# STM32WBA52 register map
File version: 0.1
CPU: CM33 r0p1, little endian, MPU, FPU, 4 interrupt priority bits
Registers are 32-bit, read-write, reset 0x0 unless marked. A register's access mark holds for its fields unless they carry their own. Offsets are from the block's base; [hi:lo] are bit positions; {n}, {i} and the like mark numbered series; <NAME> marks a mode.

## PWR — Power control
Base 0x46020800
Same registers: SEC_PWR 0x56020800
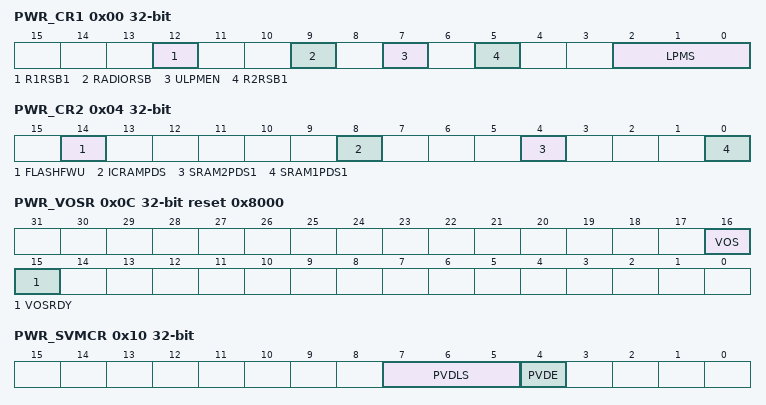
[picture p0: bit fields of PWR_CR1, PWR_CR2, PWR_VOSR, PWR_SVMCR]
0x00 PWR_CR1 — PWR control register 1
  [12] R1RSB1 — SRAM1 retention in Standby mode This bit is used to keep the SRAM1 content in Standby retention mode.
    0=SRAM1 content not retained in Standby mode; 1=SRAM1 content retained in Standby mode
  [9] RADIORSB — 2.4 GHz RADIO SRAMs (RXTXRAM and Sequence RAM) and Sleep clock retention in Standby mode. This bit is used to keep the 2.4 GHz RADIO SRAMs content in Standby retention mode and the 2.4 GHz RADIO sleep timer counter operational.
    0=2.4 GHz RADIO SRAMs and sleep timer content not retained in Standby mode; 1=2.4 GHz RADIO SRAMs and sleep timer content retained in Standby mode
  [7] ULPMEN — BOR0 ultra-low-power mode. This bit is used to reduce the consumption by configuring the BOR0 in discontinuous mode for Stop 1 and Standby modes. Discontinuous mode is only available when BOR levels 1 to 4 and PVD are disabled. Note: This bit must be set to reach the lowest power consumption in the low-power modes. Note: This bit must not be set together with autonomous peripherals using HSI16 as kernel clock. Note: When BOR level 1 to 4 or PVD is enabled continuous mode applies independent from ULPMEN.
    0=BOR0 operating in continuous (normal) mode in all operating modes; 1=BOR0 operating in discontinuous (ultra-low-power) mode in Stop 1 and Standby modes
  [5] R2RSB1 — SRAM2 retention in Standby mode This bit is used to keep the SRAM2 content in Standby retention mode.
    0=SRAM2 content not retained in Standby mode; 1=SRAM2 content retained in Standby mode
  [2:0] LPMS — Low-power mode selection These bits select the low-power mode entered when the CPU enters the SleepDeep mode. 10x: Standby mode others reserved
    0=Stop 0 mode; 1=Stop 1 mode
0x04 PWR_CR2 — PWR control register 2
  [14] FLASHFWU — Flash memory fast wakeup from Stop modes (Stop 0, 1) This bit is used to obtain the best trade-off between low-power consumption and wakeup time when exiting the Stop 0 or Stop 1 modes. When this bit is set, the Flash memory remains in normal mode in Stop 0 and Stop 1 modes, which offers a faster startup time with higher consumption.
    0=Flash memory enters low-power mode in Stop 0 and Stop 1 modes (lower-power consumption); 1=Flash memory remains in normal mode in Stop 0 and Stop 1 modes (faster wakeup time)
  [8] ICRAMPDS — ICACHE SRAM power-down in Stop modes (Stop 0, 1)
    0=ICACHE SRAM content retained in Stop modes; 1=ICACHE SRAM content lost in Stop modes
  [4] SRAM2PDS1 — SRAM2 power-down in Stop modes (Stop 0, 1) Note: The SRAM2 retention in Standby mode is controlled by R2RSB1 bit in PWR_CR1.
    0=SRAM2 content retained in Stop modes; 1=SRAM2 content lost in Stop modes
  [0] SRAM1PDS1 — SRAM1 power-down in Stop modes (Stop 0, 1) Note: The SRAM1 retention in Standby mode is controlled by R1RSB1 bit in PWR_CR1.
    0=SRAM1 content retained in Stop modes; 1=SRAM1 content lost in Stop modes
0x08 PWR_CR3 — PWR control register 3
  [2] FSTEN — Fast soft start
    0=LDO fast startup disabled (limited inrush current); 1=LDO fast startup enabled
0x0C PWR_VOSR access per field reset 0x8000 — PWR voltage scaling register
  [16] VOS rw — Voltage scaling range selection Set a and cleared by software. Cleared by hardware when entering Stop 1 mode. Access can be secured by RCC SYSCLKSEC. When secure, a non-secure read/write access is RAZ/WI. It does not generate an illegal access interrupt. This bit can be protected against unprivileged access when secure with PWR SPRIV or when non-secure with PWR NSPRIV.
    0=Range 2 (lowest power); 1=Range 1 (highest frequency)
  [15] VOSRDY ro — Ready bit for V<sub>CORE</sub> voltage scaling output selection Set and cleared by hardware. When decreasing the voltage scaling range, VOSRDY must be one before increasing the SYSCLK frequency.
    0=Not ready, voltage level < VOS selected level; 1=Ready, voltage level ≥ VOS selected level
0x10 PWR_SVMCR — PWR supply voltage monitoring control register
  [7:5] PVDLS — Programmable voltage detector level selection These bits select the voltage threshold detected by the programmable voltage detector:
    0=V<sub>PVD0</sub> ~ 2.0 V; 1=V<sub>PVD1</sub> ~ 2.2 V; 2=V<sub>PVD2</sub> ~ 2.4 V; 3=V<sub>PVD3</sub> ~ 2.5 V; 4=V<sub>PVD4</sub> ~ 2.6 V; 5=V<sub>PVD5</sub> ~ 2.8 V; 6=V<sub>PVD6</sub> ~ 2.9 V; 7=External input analog voltage PVD_IN (compared internally to VREFINT), The I/O used as PVD_IN input, must be configured in analog mode in the GPIO register
  [4] PVDE — Programmable voltage detector enable
    0=Programmable voltage detector disabled; 1=Programmable voltage detector enabled
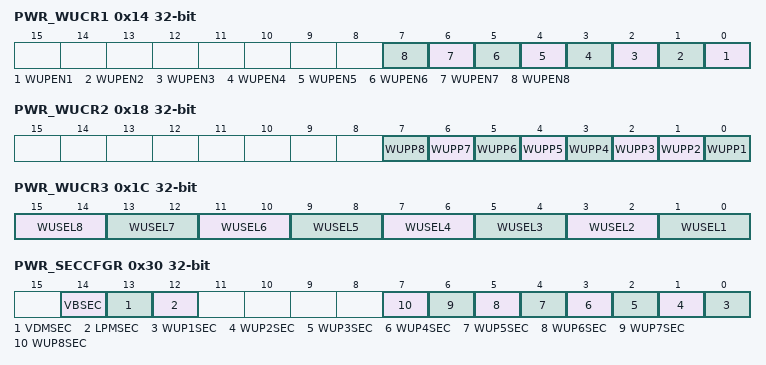
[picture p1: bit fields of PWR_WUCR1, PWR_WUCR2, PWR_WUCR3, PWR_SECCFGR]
0x14 PWR_WUCR1 — PWR wakeup control register 1
  [n-1] WUPEN{n} (n=1..8) — Wakeup and interrupt pin WKUP{n} enable Access can be secured by PWR WUP{n}SEC. When secure, a non-secure read/write access is RAZ/WI. It does not generate an illegal access interrupt. This bit can be protected against unprivileged access when secure with PWR SPRIV or when non-secure with PWR NSPRIV.
    0=Wakeup and interrupt pin WKUP{n} disabled; 1=Wakeup and interrupt pin WKUP{n} enabled
0x18 PWR_WUCR2 — PWR wakeup control register 2
  [all] fields
    0=Detection on high level (rising edge); 1=Detection on low level (falling edge)
  [n-1] WUPP{n} (n=3..8) — Wakeup pin WKUP{n} polarity This bit must be configured when WUPEN{n} = 0. Access can be secured by PWR WUP{n}SEC. When secure, a non-secure read/write access is RAZ/WI. It does not generate an illegal access interrupt. This bit can be protected against unprivileged access when secure with PWR SPRIV or when non-secure with PWR NSPRIV.
  [1] WUPP2 — Wakeup pin WKUP2 polarity This bit must be configured when WUPEN2 = 0.\ Access can be secured by PWR WUP2SEC. When secure, a non-secure read/write access is RAZ/WI. It does not generate an illegal access interrupt. This bit can be protected against unprivileged access when secure with PWR SPRIV or when non-secure with PWR NSPRIV.
  [0] WUPP1 — Wakeup pin WKUP1 polarity. This bit must be configured when WUPEN1 = 0. Access can be secured by PWR WUP1SEC. When secure, a non-secure read/write access is RAZ/WI. It does not generate an illegal access interrupt. This bit can be protected against unprivileged access when secure with PWR SPRIV or when non-secure with PWR NSPRIV.
0x1C PWR_WUCR3 — PWR wakeup control register 3
  [15:14] WUSEL8 — Wakeup and interrupt pin WKUP8 selection This field must be configured when WUPEN8 = 0. Access can be secured by PWR WUP8SEC. When secure, a non-secure read/write access is RAZ/WI. It does not generate an illegal access interrupt. This bit can be protected against unprivileged access when secure with PWR SPRIV or when non-secure with PWR NSPRIV.
    1=WKUP8_1; 2=WKUP8_2; 3=WKUP8_3 (internal source, does not generate a WKUP interrupt)
  [13:12] WUSEL7 — Wakeup and interrupt pin WKUP7 selection This field must be configured when WUPEN7 = 0. Access can be secured by PWR WUP7SEC. When secure, a non-secure read/write access is RAZ/WI. It does not generate an illegal access interrupt. This bit can be protected against unprivileged access when secure with PWR SPRIV or when non-secure with PWR NSPRIV.
    0=WKUP7_0; 1=WKUP7_1; 3=WKUP7_3 (internal source, does not generate a WKUP interrupt)
  [11:10] WUSEL6 — Wakeup and interrupt pin WKUP6 selection This field must be configured when WUPEN6 = 0. Access can be secured by PWR WUP6SEC. When secure, a non-secure read/write access is RAZ/WI. It does not generate an illegal access interrupt. This bit can be protected against unprivileged access when secure with PWR SPRIV or when non-secure with PWR NSPRIV.
    0=WKUP6_0; 1=WKUP6_1; 3=WKUP6_3 (internal source, does not generate a WKUP interrupt)
  [9:8] WUSEL5 — Wakeup and interrupt pin WKUP5 selection This field must be configured when WUPEN5 = 0. Access can be secured by PWR WUP5SEC. When secure, a non-secure read/write access is RAZ/WI. It does not generate an illegal access interrupt. This bit can be protected against unprivileged access when secure with PWR SPRIV or when non-secure with PWR NSPRIV.
    1=WKUP5_1; 2=WKUP5_2
  [7:6] WUSEL4 — Wakeup and interrupt pin WKUP4 selection This field must be configured when WUPEN4 = 0. Access can be secured by PWR WUP4SEC. When secure, a non-secure read/write access is RAZ/WI. It does not generate an illegal access interrupt. This bit can be protected against unprivileged access when secure with PWR SPRIV or when non-secure with PWR NSPRIV.
    0=WKUP4_0; 1=WKUP4_1
  [5:4] WUSEL3 — Wakeup and interrupt pin WKUP3 selection This field must be configured when WUPEN3 = 0. Access can be secured by PWR WUP3SEC. When secure, a non-secure read/write access is RAZ/WI. It does not generate an illegal access interrupt. This bit can be protected against unprivileged access when secure with PWR SPRIV or when non-secure with PWR NSPRIV.
    1=WKUP3_1; 2=WKUP3_2
  [3:2] WUSEL2 — Wakeup and interrupt pin WKUP2 selection This field must be configured when WUPEN2 = 0. Access can be secured by PWR WUP2SEC. When secure, a non-secure read/write access is RAZ/WI. It does not generate an illegal access interrupt. This bit can be protected against unprivileged access when secure with PWR SPRIV or when non-secure with PWR NSPRIV.
    1=WKUP2_1
  [1:0] WUSEL1 — Wakeup and interrupt pin WKUP1 selection This field must be configured when WUPEN1 = 0. Access can be secured by PWR WUP1SEC. When secure, a non-secure read/write access is RAZ/WI. It does not generate an illegal access interrupt. This bit can be protected against unprivileged access when secure with PWR SPRIV or when non-secure with PWR NSPRIV.
    0=WKUP1_0; 1=WKUP1_1
0x28 PWR_DBPR — PWR disable Backup domain register
  [0] DBP — Disable Backup domain write protection In reset state, all registers and SRAM in Backup domain are protected against parasitic write access. This bit must be set to enable the write access to these registers.
    0=Write access to Backup domain disabled; 1=Write access to Backup domain enabled
0x30 PWR_SECCFGR — PWR security configuration register
  [14] VBSEC — Backup domain secure protection
    0=PWR_DBPR can be read and written with secure or non-secure access; 1=PWR_DBPR can be read and written only with secure access
  [13] VDMSEC — Voltage detection secure protection
    0=PWR_SVMCR and PWR_CR3 can be read and written with secure or non-secure access; 1=PWR_SVMCR and PWR_CR3 can be read and written only with secure access
  [12] LPMSEC — Low-power modes secure protection
    0=PWR_CR1, PWR_CR2 and CSSF in the PWR_SR can be read and written with secure or non-secure access; 1=PWR_CR1, PWR_CR2, and CSSF in the PWR_SR can be read and written only with secure access
  [n-1] WUP{n}SEC (n=1..8) — WUP{n} secure protection
    0=Bits related to the WKUP{n} pin in PWR_WUCR1, PWR_WUCR2, PWR_WUCR3 and PWR_WUSCR can be read and written with secure or non-secure access; 1=Bits related to the WKUP{n} pin in PWR_WUCR1, PWR_WUCR2, PWR_WUCR3 and PWR_WUSCR can be read and written only with secure access
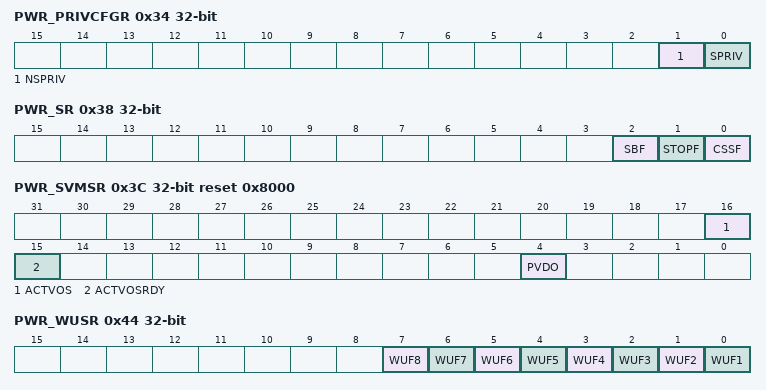
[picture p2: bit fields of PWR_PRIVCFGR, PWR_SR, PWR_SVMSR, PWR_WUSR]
0x34 PWR_PRIVCFGR — PWR privilege control register
  [1] NSPRIV — PWR non-secure functions privilege configuration This bit is set and reset by software. It can be written only by privileged access, secure or non-secure.
    0=Read and write to PWR non-secure functions can be done by privileged or unprivileged access; 1=Read and write to PWR non-secure functions can be done by privileged access only
  [0] SPRIV — PWR secure functions privilege configuration This bit is set and reset by software. It can be written only by a secure privileged access.
    0=Read and write to PWR secure functions can be done by privileged or unprivileged access; 1=Read and write to PWR secure functions can be done by privileged access only
0x38 PWR_SR access per field — PWR status register
  [2] SBF ro — Standby flag This bit is set by hardware when the device enters the Standby mode and the CPU restart from its reset vector. It’s cleared by writing 1 to the CSSF bit, or by a power-on reset. It is not cleared by the system reset.
    0=The device did not enter Standby mode; 1=The device entered Standby mode
  [1] STOPF ro — Stop flag This bit is set by hardware when the device enters a Stop or Standby mode at the same time as the sysclk has been set by hardware to select HSI16. It’s cleared by software by writing 1 to the CSSF bit and by hardware when SBF is set.
    0=The device did not enter any Stop mode; 1=The device entered a Stop mode
  [0] CSSF wo — Clear Stop and Standby flags Access can be secured by PWR LPMSEC. When secure, a non-secure read/write access is RAZ/WI. It does not generate an illegal access interrupt. This bit can be protected against unprivileged access when secure with PWR SPRIV or when non-secure with PWR NSPRIV. Writing 1 to this bit clears the STOPF and SBF flags.
0x3C PWR_SVMSR ro reset 0x8000 — PWR supply voltage monitoring status register
  [16] ACTVOS — VOS currently applied to V<sub>CORE</sub> This field provides the last VOS value.
    0=Range 2 (lowest power); 1=Range 1 (highest frequency)
  [15] ACTVOSRDY — Voltage level ready for currently used VOS
    0=V<sub>CORE</sub> is above or below the current voltage scaling provided by ACTVOS; 1=V<sub>CORE </sub>is equal to the current voltage scaling provided by ACTVOS
  [4] PVDO — Programmable voltage detector output
    0=V<sub>DD</sub> is equal or above the PVD threshold selected by PVDLS[2:0]; 1=V<sub>DD </sub>is below the PVD threshold selected by PVDLS[2:0]
0x44 PWR_WUSR ro — PWR wakeup status register
  [7] WUF8 — Wakeup and interrupt pending flag 8 This bit is set when a wakeup event is detected on WKUP8 pin. This bit is cleared by writing 1 in the CWUF8 bit of PWR_WUSCR when WUSEL8 ≠ 11, or by hardware when WUPEN8 = 0. When WUSEL8 = 11, this bit is cleared by hardware when all associated internal wakeup source are cleared. When WUSEL8 = 11, no WKUP interrupt is generated
  [6] WUF7 — Wakeup and interrupt pending flag 7 This bit is set when a wakeup event is detected on WKUP7 pin. This bit is cleared by writing 1 in the CWUF7 bit of PWR_WUSCR when WUSEL7 ≠ 11, or by hardware when WUPEN7 = 0. When WUSEL7 = 11, this bit is cleared by hardware when all associated internal wakeup source are cleared. When WUSEL7 = 11, no WKUP interrupt is generated.
  [5] WUF6 — Wakeup and interrupt pending flag 6 This bit is set when a wakeup event is detected on WKUP6 pin. This bit is cleared by writing 1 in the CWUF6 bit of PWR_WUSCR when WUSEL6 ≠ 11, or by hardware when WUPEN6 = 0. When WUSEL6 = 11, this bit is cleared by hardware when all associated internal wakeup source are cleared. When WUSEL6 = 11, no WKUP interrupt is generated
  [n-1] WUF{n} (n=1..5) — Wakeup and interrupt pending flag {n} This bit is set when a wakeup event is detected on WKUP{n} pin. This bit is cleared by writing 1 in the CWUF{n} bit of PWR_WUSCR or by hardware when WUPEN{n} = 0.
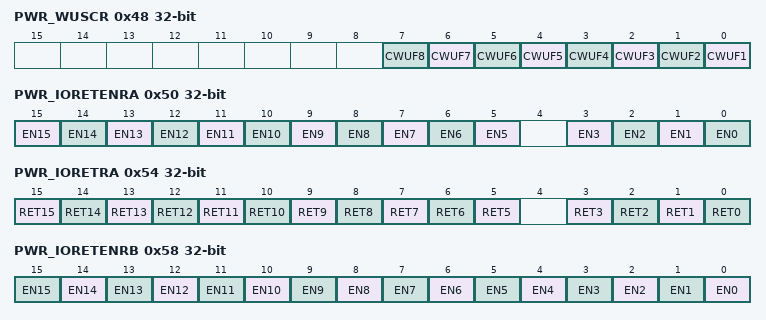
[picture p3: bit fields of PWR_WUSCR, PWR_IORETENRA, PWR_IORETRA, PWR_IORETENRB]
0x48 PWR_WUSCR wo — PWR wakeup status clear register
  [n-1] CWUF{n} (n=1..8) — Clear wakeup flag {n} Access can be secured by PWR WUP{n}SEC. When secure, a non-secure read/write access is RAZ/WI. It does not generate an illegal access interrupt. This bit can be protected against unprivileged access when secure with PWR SPRIV or when non-secure with PWR NSPRIV. Writing 1 to this bit clears the WUF{n} flag in PWR_WUSR.
0x50 PWR_IORETENRA — PWR port A Standby IO retention enable register
  [n] EN{n} (n=5..15) — Port A Standby GPIO retention enable Access can be secured by GPIOA SECy. When secure, a non-secure read/write access is RAZ/WI. It does not generate an illegal access interrupt. This bit can be protected against unprivileged access when secure with PWR SPRIV or when non-secure with PWR NSPRIV.
    0=PAy Standby GPIO retention feature disabled; 1=PAy Standby GPIO retention feature enabled
  [n] EN{n} (n=0..3) — Port A Standby GPIO retention enable Access can be protected by GPIOA SECy, privilege protection is controlled by PWR SPRIV or PWR NSPRIV. When set, each bit enables the Standby GPIO retention feature for PAy
0x54 PWR_IORETRA — PWR port A Standby IO retention status register
  [all] fields
    1=Set by hardware when Standby GPIO PAy is enabled in PWR_IORETENRA and Standby mode is entered. Standby GPIO retention PAy active.; 0=Cleared by software, writing 0. Standby GPIO retention PAy disabled.
  [n] RET{n} (n=5..15) — Port A Standby GPIO retention active Access can be secured by GPIOA SECy. When secure, a non-secure read/write access is RAZ/WI. It does not generate an illegal access interrupt. This bit can be protected against unprivileged access when secure with PWR SPRIV or when non-secure with PWR NSPRIV.
  [n] RET{n} (n=0..3) — Port A Standby GPIO retention active Access can be protected by GPIOA SECy, privilege protection is controlled by PWR SPRIV or PWR NSPRIV.
0x58 PWR_IORETENRB — PWR port B Standby IO retention enable register
  [all] fields
    0=PBy Standby GPIO retention feature disabled; 1=PBy Standby GPIO retention feature enabled
  [n] EN{n} (n=0..15) — Port B Standby GPIO retention enable Access can be secured by GPIOB SECy. When secure, a non-secure read/write access is RAZ/WI. It does not generate an illegal access interrupt. This bit can be protected against unprivileged access when secure with PWR SPRIV or when non-secure with PWR NSPRIV.
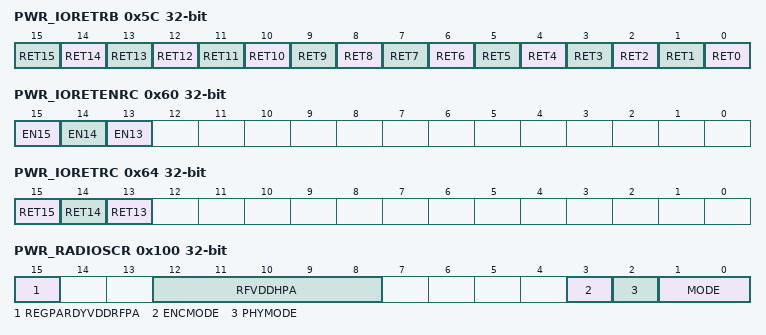
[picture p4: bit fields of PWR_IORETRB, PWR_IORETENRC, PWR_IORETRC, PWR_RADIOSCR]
0x5C PWR_IORETRB — PWR port B Standby IO retention status register
  [all] fields
    1=Set by hardware when Standby GPIO PBy is enabled in PWR_IORETENRB and Standby mode is entered. Standby GPIO retention PBy active.; 0=Cleared by software, writing 0. Standby GPIO retention PBy disabled..
  [n] RET{n} (n=0..15) — Port B Standby GPIO retention active Access can be secured by GPIOB SECy. When secure, a non-secure read/write access is RAZ/WI. It does not generate an illegal access interrupt. This bit can be protected against unprivileged access when secure with PWR SPRIV or when non-secure with PWR NSPRIV.
0x60 PWR_IORETENRC — PWR port C Standby IO retention enable register
  [all] fields
    0=PCy Standby GPIO retention feature disabled; 1=PCy Standby GPIO retention feature enabled
  [15] EN15 — Port C Standby GPIO retention enable Access can be secured by GPIOC SECy. When secure, a non-secure read/write access is RAZ/WI. It does not generate an illegal access interrupt. This bit can be protected against unprivileged access when secure with PWR SPRIV or when non-secure with PWR NSPRIV.
  [14] EN14 — Port C Standby GPIO retention enable Access can be secured by GPIOC SECy. When secure, a non-secure read/write access is RAZ/WI. It does not generate an illegal access interrupt. This bit can be protected against unprivileged access when secure with PWR SPRIV or when non-secure with PWR NSPRIV.
  [13] EN13 — Port C Standby GPIO retention enable Access can be secured by GPIOC SECy. When secure, a non-secure read/write access is RAZ/WI. It does not generate an illegal access interrupt. This bit can be protected against unprivileged access when secure with PWR SPRIV or when non-secure with PWR NSPRIV.
0x64 PWR_IORETRC — PWR port C Standby IO retention status register
  [all] fields
    1=Set by hardware when Standby GPIO PCy is enabled in PWR_IORETENRC and Standby mode is entered. Standby GPIO retention PCy active.; 0=Cleared by software, writing 0. Standby GPIO retention PCy disabled.
  [15] RET15 — Port C Standby GPIO retention active Access can be secured by GPIOC SECy. When secure, a non-secure read/write access is RAZ/WI. It does not generate an illegal access interrupt. This bit can be protected against unprivileged access when secure with PWR SPRIV or when non-secure with PWR NSPRIV.
  [14] RET14 — Port C Standby GPIO retention active Access can be secured by GPIOC SECy. When secure, a non-secure read/write access is RAZ/WI. It does not generate an illegal access interrupt. This bit can be protected against unprivileged access when secure with PWR SPRIV or when non-secure with PWR NSPRIV.
  [13] RET13 — Port C Standby GPIO retention active Access can be secured by GPIOC SECy. When secure, a non-secure read/write access is RAZ/WI. It does not generate an illegal access interrupt. This bit can be protected against unprivileged access when secure with PWR SPRIV or when non-secure with PWR NSPRIV.
0x88 PWR_IORETENRH — PWR port H Standby IO retention enable register
  [3] EN3 — Port H Standby GPIO retention enable Access can be secured by GPIOH SEC3. When secure, a non-secure read/write access is RAZ/WI. It does not generate an illegal access interrupt. This bit can be protected against unprivileged access when secure with PWR SPRIV or when non-secure with PWR NSPRIV.
    0=PHy Standby GPIO retention feature disabled; 1=PHy Standby GPIO retention feature enabled
0x8C PWR_IORETRH — PWR port H Standby IO retention status register
  [3] RET3 — Port H Standby GPIO retention active Access can be secured by GPIOH SEC3. When secure, a non-secure read/write access is RAZ/WI. It does not generate an illegal access interrupt. This bit can be protected against unprivileged access when secure with PWR SPRIV or when non-secure with PWR NSPRIV.
    1=Set by hardware when Standby GPIO PHy is enabled in PWR_IORETENRH and Standby mode is entered. Standby GPIO retention PHy active.; 0=Cleared by software, writing 0. Standby GPIO retention PHy disabled.
0x100 PWR_RADIOSCR ro — PWR 2.4 GHz RADIO status and control register
  [15] REGPARDYVDDRFPA — Ready bit for V<sub>DDHPA</sub> voltage level when selecting VDDRFPA input. Note: REGPARDYVDDRFPA does not allow to detect correct V<sub>DDHPA</sub> voltage level when request to lower the level.
    0=Not ready, V<sub>DDHPA</sub> voltage level < REGPAVOS selected supply level; 1=Ready, V<sub>DDHPA</sub> voltage level ≥ REGPAVOS selected supply level
  [12:8] RFVDDHPA — 2.4 GHz RADIO VDDHPA control word. Bits [3:0] see Table 81: PA output power table format for definition. Bit [4] rf_event.
  [3] ENCMODE — 2.4 GHz RADIO encryption function operating mode
    0=2.4 GHz RADIO encryption function disabled; 1=2.4 GHz RADIO encryption function enabled
  [2] PHYMODE — 2.4 GHz RADIO PHY operating mode
    0=2.4 GHz RADIO Sleep mode; 1=2.4 GHz RADIO Standby mode
  [1:0] MODE — 2.4 GHz RADIO operating mode. 1x: 2.4 GHz RADIO active mode
    0=2.4 GHz RADIO deep sleep mode; 1=2.4 GHz RADIO sleep mode
